# LPC43xx register map
File version: 10
CPU: CM4 r0p0, little endian, no MPU, no FPU, 3 interrupt priority bits
Registers are 32-bit, read-write, reset 0x0 unless marked. A register's access mark holds for its fields unless they carry their own. Offsets are from the block's base; [hi:lo] are bit positions; {n}, {i} and the like mark numbered series; 'fields as' and 'values as' point back to an identical list.

## ADCHS — 12-bit Analog-to-Digital Converter High-Speed (ADCHS)
Base 0x400F0000
0x00 FLUSH wo — Flushes FIFO
  [0] FIFO_FLUSH — 1= fifo is cleared
0x04 DMA_REQ reset 0x1 — Set or clear DMA write request
  [0] DMA_REQ_WR — 1 = Dma_req_wr is set (initially used to fill second table), 0 = Dma_req_wr is cleared
0x08 FIFO_STS ro — Indicates FIFO fill level status
  [4:0] LEVEL — 0 = FIFO is empty 1...15 = FIFO is partially full 16 = FIFO is full
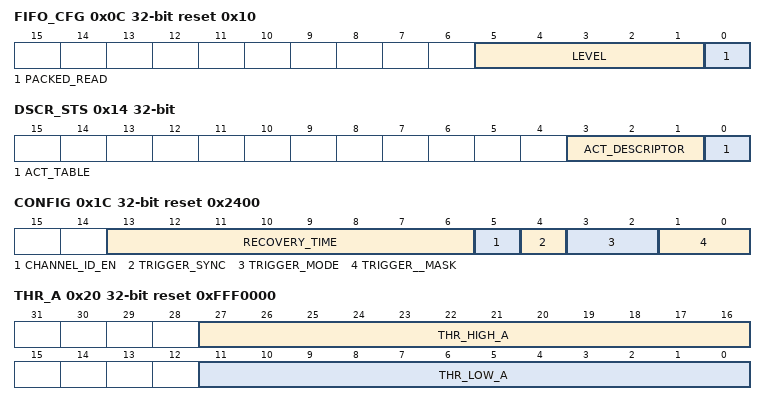
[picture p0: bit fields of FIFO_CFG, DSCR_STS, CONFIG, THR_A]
0x0C FIFO_CFG reset 0x10 — Configures FIFO fill level that triggers interrupt and packing 1 or 2 samples per word.
  [5:1] LEVEL — When the FIFO contains more or equal than FIFO_LEVEL samples interrupt flag FIFO_FULL interrupt will be set and DMA_Read_Req will be raised.
  [0] PACKED_READ — 0 = one sample is packed in one 32-bit read cycle 1 = two samples are packed in one 32-bit read cycle
0x10 TRIGGER wo — Enable software trigger to start descriptor processing
  [0] SW_TRIGGER — Auto cleared
0x14 DSCR_STS — Indicates active descriptor table and descriptor entry
  [3:1] ACT_DESCRIPTOR — ID of the descriptor that is active.
  [0] ACT_TABLE — 0 = table 0 is active 1 = table 1 is active.
0x18 POWER_DOWN reset 0x1 — Set or clear power down mode
  [0] PD_CTRL — 0 = disable power down mode. Register holds value until set by writing 1 to this bit or by descriptor processor when descriptor field POWER_DOWN is set. 1 = enable power down mode. Register holds value until cleared by writing 0 to this bit or by descriptor processor when waking up RECOVERY_TIME before a conversion.
0x1C CONFIG reset 0x2400 — Configures external trigger mode, store channel ID in FIFO and walk-up recovery time from power down.
  [13:6] RECOVERY_TIME — ADC recovery time from power down
  [5] CHANNEL_ID_EN — 0 = do not add channel ID to FIFO output data 1 = add channel ID to FIFO output data
  [4] TRIGGER_SYNC — 0 = do not synchronize external trigger input 1 = synchronize external trigger input
  [3:2] TRIGGER_MODE — 00 = rising external trigger 01 = falling external trigger 10 = low external trigger 11 = high external trigger
  [1:0] TRIGGER__MASK — 00 = triggers off 01 = software trigger only 10 = external trigger only 11 = both triggers allowed
0x20 THR_A reset 0xFFF0000 — Configures window comparator A levels.
  [27:16] THR_HIGH_A — High Compare Threshold Register A: Contains the upper threshold level for automatic threshold comparison for any channels linked to threshold pair A.
  [11:0] THR_LOW_A — Low Compare Threshold Register A: Contains the lower threshold level for automatic threshold comparison for any channels linked to threshold pair A.
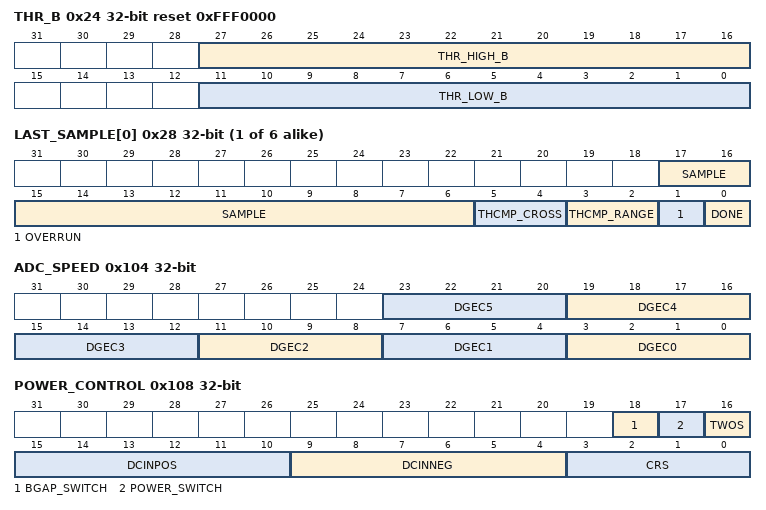
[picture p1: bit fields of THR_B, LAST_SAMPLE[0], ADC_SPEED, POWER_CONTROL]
0x24 THR_B reset 0xFFF0000 — Configures window comparator B levels.
  [27:16] THR_HIGH_B — High Compare Threshold Register B: Contains the upper threshold level for automatic threshold comparison for any channels linked to threshold pair A.
  [11:0] THR_LOW_B — Low Compare Threshold Register B: Contains the lower threshold level for automatic threshold comparison for any channels linked to threshold pair A.
{0x28+4i} LAST_SAMPLE[{i}] (i=0..5) ro — Contains last converted sample of input M [M=0..5) and result of window comparator.
  [17:6] SAMPLE — 12-Bit value of last converted sample for this channel
  [5:4] THCMP_CROSS — Threshold Crossing Comparison result 00: No Threshold Crossing detected 01: Downward Threshold Crossing detected 10: Upward Threshold Crossing detected 11: Reserved
  [3:2] THCMP_RANGE — Threshold Range Comparison result 00: In Range 01: Below Range 10: Above Range 11: Reserved
  [1] OVERRUN — This bit will be set to a 1 if a new conversion on this channel completes and overwrites the previous contents of the RESULT field before it has been read - i.e. while the DONE bit is set. This bit is cleared, along with the DONE bit, whenever this register is read. This bit (in any of the registers) will cause an overrun interrupt request to be asserted if the overrun interrupt is enabled.
  [0] DONE — This bit is set to 1 when an A/D conversion on this channel completes. This bit is cleared whenever this register is read.
0x104 ADC_SPEED — ADC speed control
  [4n+3:4n] DGEC{n} (n=0..5) — Speed{n}
0x108 POWER_CONTROL — Configures ADC power vs. speed, DC-in biasing, output format and power gating.
  [18] BGAP_SWITCH — 0 = ADC band gap reference is powered down 1 = ADC band gap reference is active
  [17] POWER_SWITCH — 0 = ADC is powered down 1 = ADC is active
  [16] TWOS — Output data format selection 0 = offset binary 1 = two's complement
  [15:10] DCINPOS — AC-DC coupling selection 0 = No dc bias 1 = DC bias on vin_pos side
  [9:4] DCINNEG — AC-DC coupling selection 0 = No dc bias 1 = DC bias on vin_neg side
  [3:0] CRS — current setting for power versus speed programming
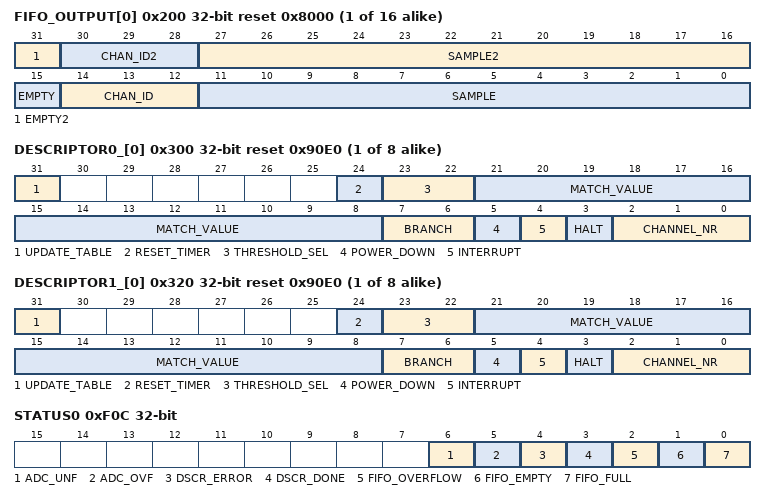
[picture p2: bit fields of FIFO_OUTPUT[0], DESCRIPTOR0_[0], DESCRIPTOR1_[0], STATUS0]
{0x200+4i} FIFO_OUTPUT[{i}] (i=0..15) ro reset 0x8000 — FIFO output mapped to 16 consecutive address locations. An output contains the value and input channel ID of one or two converted samples
  [31] EMPTY2 — 0: FIFO not empty 1: FIFO empty and PACKED_READ is set
  [30:28] CHAN_ID2 — Channel number of second converted sample This field is only valid if CHANNEL_ID_EN and PACKED_READ are set else it is 0x0
  [27:16] SAMPLE2 — Value of second converted sample. This field is only valid if PACKED_READ is set else it is 0x0
  [15] EMPTY — 0: FIFO not empty 1: FIFO empty
  [14:12] CHAN_ID — Channel number of first converted sample: 000: channel _0 or CHANNEL_ID_EN =0 001: channel _1 010: channel _2 011: channel _3 100: channel _4 101: channel _5 110: reserved 111: recovery_ error
  [11:0] SAMPLE — Value of first converted sample
{0x300+4i} DESCRIPTOR0_[{i}] (i=0..7) reset 0x90E0 — Table 0 descriptor n, n= 0 to 7
  [31] UPDATE_TABLE — 1: Update table with all 8 descriptors of this table. Descriptors of this table that are written without this bit set are not updated until any descriptor of this table is written with this bit set. This field is write only. A read returns 0x0.
  [24] RESET_TIMER — 1: reset descriptor timer.
  [23:22] THRESHOLD_SEL — Indicates which threshold comparison level register set is to be used: 00: no comparison, 01: THR_A. 10: THR_B. 11: Reserved
  [21:8] MATCH_VALUE — Evaluate this descriptor when descriptor timer value is equal to match value.
  [7:6] BRANCH — 00: Continue with next descriptor (wraps around after top). 01: Branch to the first descriptor in this table. 10: Swap tables and branch to the first descriptor of the new table. 11: reserved (do not store sample). Continue with next descriptor (wraps around after top).
  [5] POWER_DOWN — 1: Power down after this conversion.
  [4] INTERRUPT — 1: Raise interrupt when ADC result is available
  [3] HALT — 0: After this descriptor continue with the next descriptor. 1: halt after this descriptor is processed. Restart at a new trigger.
  [2:0] CHANNEL_NR — 0: convert input 0 1: convert input 1 2: convert input 2 3: convert input 3 4: convert input 4 5: convert input 5 6,7: reserved
{0x320+4i} DESCRIPTOR1_[{i}] (i=0..7) reset 0x90E0 — Table 1 descriptors n, n=0 to 7
  fields as DESCRIPTOR0_[0]
0xF00 CLR_EN0 wo — Interrupt 0 clear mask
  [6:0] CEN0 — Interrupt clear enable
0xF04 SET_EN0 wo — Interrupt 0 set mask
  [6:0] SEN0 — Interrupt set enable
0xF08 MASK0 ro — Interrupt 0 mask
  [6:0] M0 — Interrupt enable
0xF0C STATUS0 ro — Interrupt 0 status. Interrupt 0 contains FIFO fill level, descriptor status and ADC range under/overflow
  [6] ADC_UNF — Converted sample value was under range of the 12 bit output code.
  [5] ADC_OVF — Converted sample value was over range of the 12 bit output code.
  [4] DSCR_ERROR — The ADC was not fully woken up when a sample was converted and the conversion results is unreliable
  [3] DSCR_DONE — The descriptor INTERRUPT field was enabled and its sample is converted.
  [2] FIFO_OVERFLOW — FIFO was full; conversion sample is not stored and lost
  [1] FIFO_EMPTY — 0: FIFO is not empty 1: FIFO is empty
  [0] FIFO_FULL — 0: number of samples in FIFO less than or equal to FIFO_LEVEL 1: number of samples in FIFO is more than FIFO_LEVEL
0xF10 CLR_STAT0 wo — Interrupt 0 clear status
  [6:0] CSTAT0 — Interrupt clear status
0xF14 SET_STAT0 wo — Interrupt 0 set status
  [6:0] SSTAT0 — Interrupt set status
0xF20 CLR_EN1 wo — Interrupt 1 mask clear enable.
  [29:0] CEN1 — Interrupt clear enable
0xF24 SET_EN1 wo — Interrupt 1 mask set enable
  [29:0] SEN1 — Interrupt set enable
0xF28 MASK1 ro — Interrupt 1 mask
  [29:0] M1 — Interrupt enable
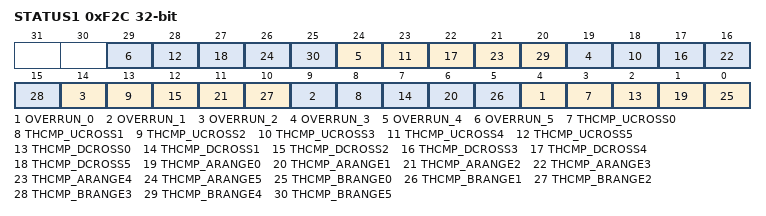
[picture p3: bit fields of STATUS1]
0xF2C STATUS1 ro — Interrupt 1 status. Interrupt 1 contains window comparator results and register last LAST_SAMPLE[M] overrun.
  [5n+4] OVERRUN_{n} (n=0..5) — A new conversion on channel m completed and has overwritten the previous contents of register LAST_SAMPLE [{n}] before it has been read
  [5n+3] THCMP_UCROSS{n} (n=0..5) — Input channel {n} result upward threshold crossing detected
  [5n+2] THCMP_DCROSS{n} (n=0..5) — Input channel {n} result downward threshold crossing detected
  [5n+1] THCMP_ARANGE{n} (n=0..5) — Input channel {n} result above range
  [5n] THCMP_BRANGE{n} (n=0..5) — Input channel {n} result below range
0xF30 CLR_STAT1 wo — Interrupt 1 clear status
  [29:0] CSTAT1 — Interrupt clear status
0xF34 SET_STAT1 wo — Interrupt 1 set status
  [29:0] SSTAT1 — Interrupt set status
